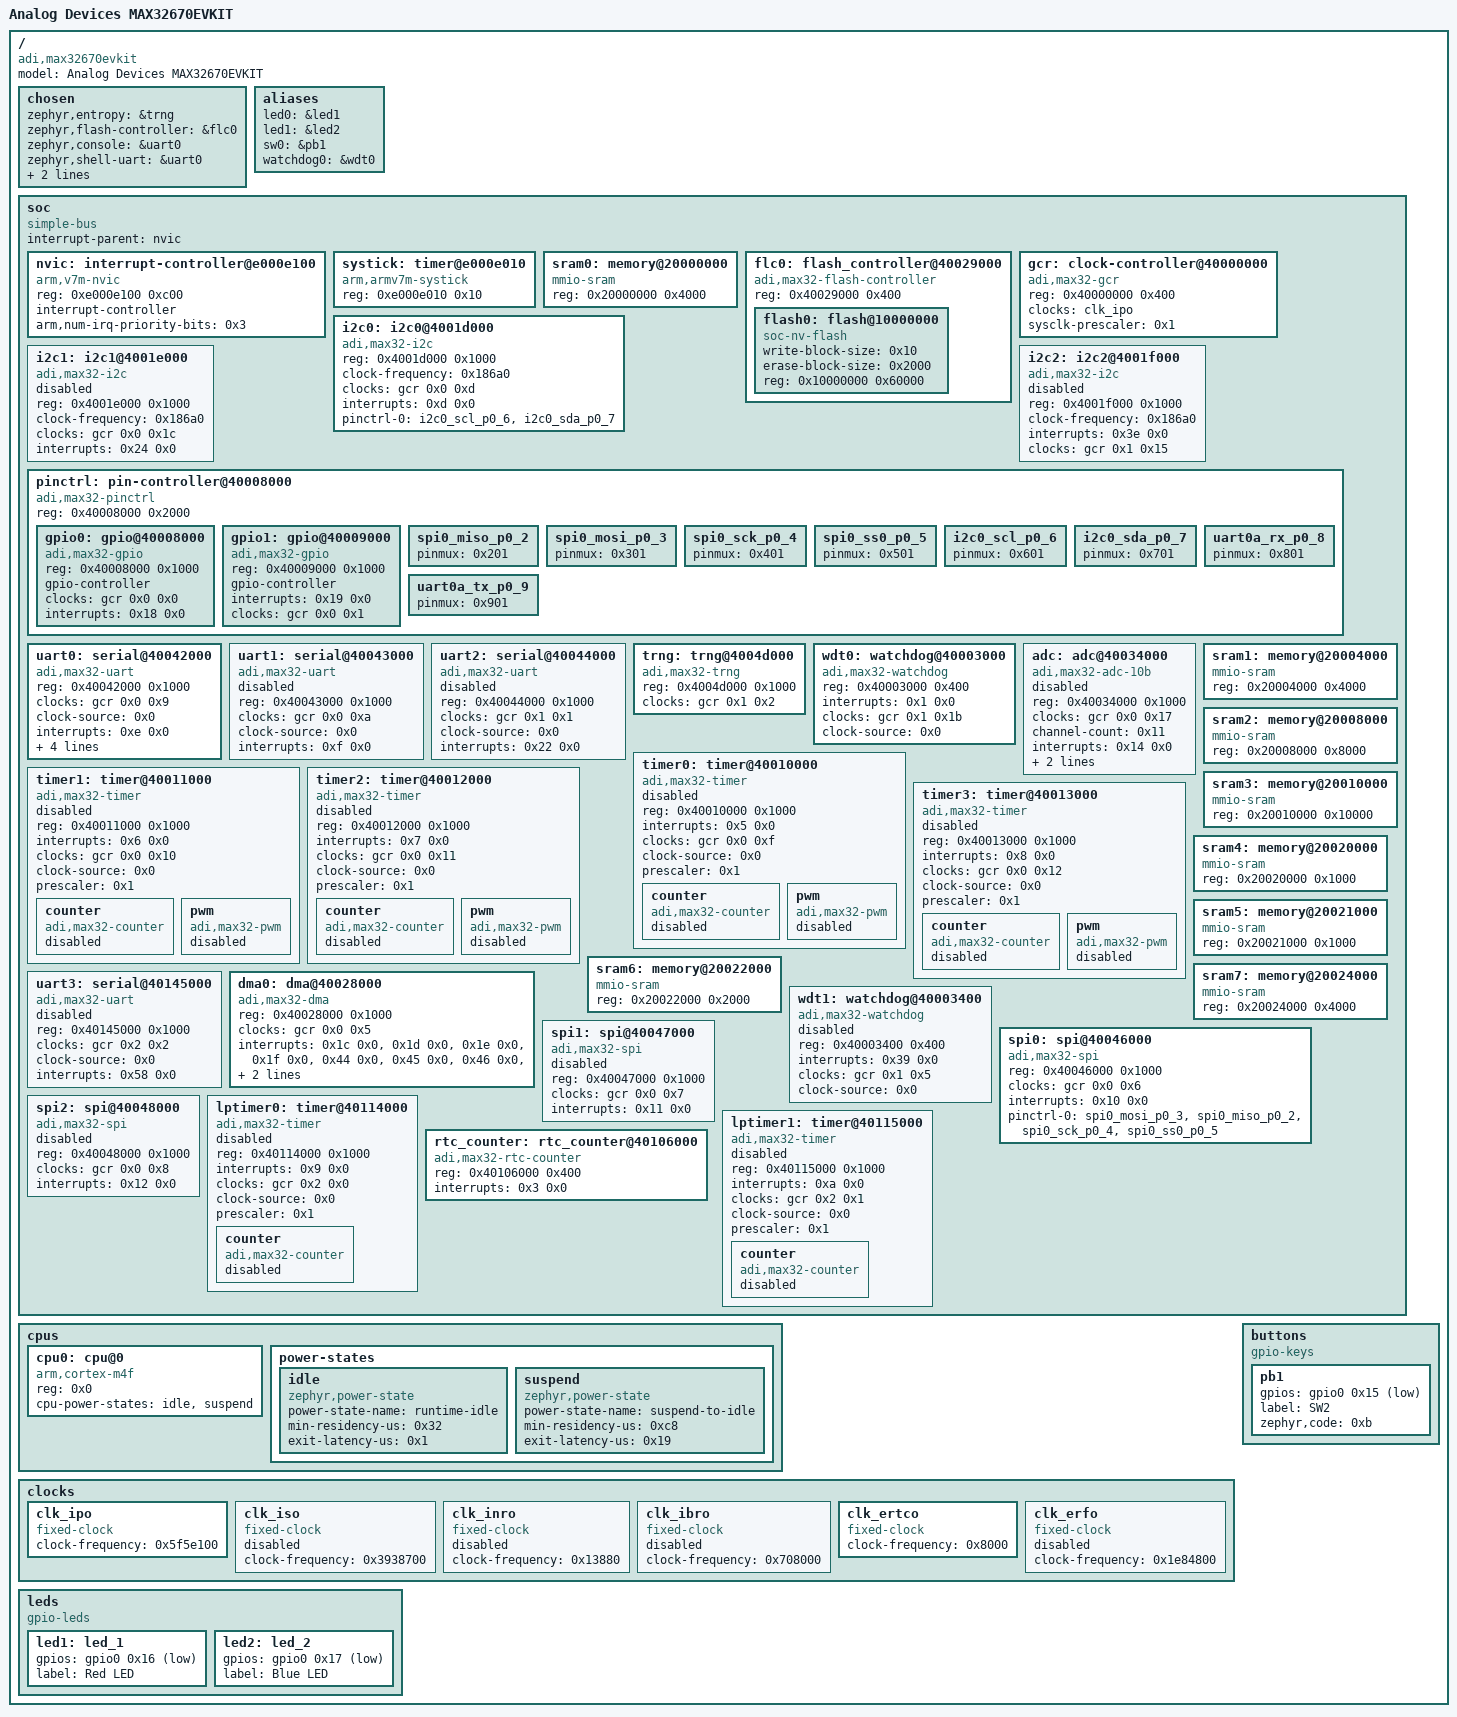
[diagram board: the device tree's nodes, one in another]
/dts-v1/;

/* node '/' defined in zephyr/dts/common/skeleton.dtsi:9 */
/ {
	#address-cells = < 0x1 >;               /* in zephyr/dts/common/skeleton.dtsi:10 */
	#size-cells = < 0x1 >;                  /* in zephyr/dts/common/skeleton.dtsi:11 */
	model = "Analog Devices MAX32670EVKIT"; /* in zephyr/boards/adi/max32670evkit/max32670evkit.dts:15 */
	compatible = "adi,max32670evkit";       /* in zephyr/boards/adi/max32670evkit/max32670evkit.dts:16 */

	/* node '/chosen' defined in zephyr/dts/common/skeleton.dtsi:13 */
	chosen {
		zephyr,entropy = &trng;          /* in zephyr/dts/arm/adi/max32/max32xxx.dtsi:17 */
		zephyr,flash-controller = &flc0; /* in zephyr/dts/arm/adi/max32/max32xxx.dtsi:18 */
		zephyr,console = &uart0;         /* in zephyr/boards/adi/max32670evkit/max32670evkit.dts:19 */
		zephyr,shell-uart = &uart0;      /* in zephyr/boards/adi/max32670evkit/max32670evkit.dts:20 */
		zephyr,sram = &sram3;            /* in zephyr/boards/adi/max32670evkit/max32670evkit.dts:21 */
		zephyr,flash = &flash0;          /* in zephyr/boards/adi/max32670evkit/max32670evkit.dts:22 */
	};

	/* node '/aliases' defined in zephyr/dts/common/skeleton.dtsi:15 */
	aliases {
		led0 = &led1;      /* in zephyr/boards/adi/max32670evkit/max32670evkit.dts:51 */
		led1 = &led2;      /* in zephyr/boards/adi/max32670evkit/max32670evkit.dts:52 */
		sw0 = &pb1;        /* in zephyr/boards/adi/max32670evkit/max32670evkit.dts:53 */
		watchdog0 = &wdt0; /* in zephyr/boards/adi/max32670evkit/max32670evkit.dts:54 */
	};

	/* node '/soc' defined in zephyr/dts/arm/armv7-m.dtsi:6 */
	soc {
		#address-cells = < 0x1 >;     /* in zephyr/dts/arm/armv7-m.dtsi:7 */
		#size-cells = < 0x1 >;        /* in zephyr/dts/arm/armv7-m.dtsi:8 */
		compatible = "simple-bus";    /* in zephyr/dts/arm/armv7-m.dtsi:9 */
		interrupt-parent = < &nvic >; /* in zephyr/dts/arm/armv7-m.dtsi:10 */
		ranges;                       /* in zephyr/dts/arm/armv7-m.dtsi:11 */

		/* node '/soc/interrupt-controller@e000e100' defined in zephyr/dts/arm/armv7-m.dtsi:13 */
		nvic: interrupt-controller@e000e100 {
			#address-cells = < 0x1 >;            /* in zephyr/dts/arm/armv7-m.dtsi:14 */
			compatible = "arm,v7m-nvic";         /* in zephyr/dts/arm/armv7-m.dtsi:15 */
			reg = < 0xe000e100 0xc00 >;          /* in zephyr/dts/arm/armv7-m.dtsi:16 */
			interrupt-controller;                /* in zephyr/dts/arm/armv7-m.dtsi:17 */
			#interrupt-cells = < 0x2 >;          /* in zephyr/dts/arm/armv7-m.dtsi:18 */
			arm,num-irq-priority-bits = < 0x3 >; /* in zephyr/dts/arm/adi/max32/max32xxx.dtsi:337 */
			phandle = < 0x1 >;                   /* in zephyr/dts/arm/armv7-m.dtsi:10 */
		};

		/* node '/soc/timer@e000e010' defined in zephyr/dts/arm/armv7-m.dtsi:21 */
		systick: timer@e000e010 {
			compatible = "arm,armv7m-systick"; /* in zephyr/dts/arm/armv7-m.dtsi:22 */
			reg = < 0xe000e010 0x10 >;         /* in zephyr/dts/arm/armv7-m.dtsi:23 */
		};

		/* node '/soc/memory@20000000' defined in zephyr/dts/arm/adi/max32/max32xxx.dtsi:98 */
		sram0: memory@20000000 {
			compatible = "mmio-sram";    /* in zephyr/dts/arm/adi/max32/max32xxx.dtsi:99 */
			reg = < 0x20000000 0x4000 >; /* in zephyr/dts/arm/adi/max32/max32670.dtsi:12 */
		};

		/* node '/soc/flash_controller@40029000' defined in zephyr/dts/arm/adi/max32/max32xxx.dtsi:103 */
		flc0: flash_controller@40029000 {
			compatible = "adi,max32-flash-controller"; /* in zephyr/dts/arm/adi/max32/max32xxx.dtsi:104 */
			reg = < 0x40029000 0x400 >;                /* in zephyr/dts/arm/adi/max32/max32xxx.dtsi:105 */
			#address-cells = < 0x1 >;                  /* in zephyr/dts/arm/adi/max32/max32xxx.dtsi:107 */
			#size-cells = < 0x1 >;                     /* in zephyr/dts/arm/adi/max32/max32xxx.dtsi:108 */
			status = "okay";                           /* in zephyr/dts/arm/adi/max32/max32xxx.dtsi:109 */

			/* node '/soc/flash_controller@40029000/flash@10000000' defined in zephyr/dts/arm/adi/max32/max32xxx.dtsi:111 */
			flash0: flash@10000000 {
				compatible = "soc-nv-flash";   /* in zephyr/dts/arm/adi/max32/max32xxx.dtsi:112 */
				write-block-size = < 0x10 >;   /* in zephyr/dts/arm/adi/max32/max32xxx.dtsi:114 */
				erase-block-size = < 0x2000 >; /* in zephyr/dts/arm/adi/max32/max32xxx.dtsi:115 */
				reg = < 0x10000000 0x60000 >;  /* in zephyr/dts/arm/adi/max32/max32670.dtsi:16 */
			};
		};

		/* node '/soc/clock-controller@40000000' defined in zephyr/dts/arm/adi/max32/max32xxx.dtsi:119 */
		gcr: clock-controller@40000000 {
			reg = < 0x40000000 0x400 >;   /* in zephyr/dts/arm/adi/max32/max32xxx.dtsi:120 */
			compatible = "adi,max32-gcr"; /* in zephyr/dts/arm/adi/max32/max32xxx.dtsi:121 */
			#clock-cells = < 0x2 >;       /* in zephyr/dts/arm/adi/max32/max32xxx.dtsi:122 */
			clocks = < &clk_ipo >;        /* in zephyr/dts/arm/adi/max32/max32xxx.dtsi:123 */
			sysclk-prescaler = < 0x1 >;   /* in zephyr/dts/arm/adi/max32/max32xxx.dtsi:124 */
			status = "okay";              /* in zephyr/dts/arm/adi/max32/max32xxx.dtsi:125 */
			phandle = < 0x3 >;            /* in zephyr/dts/arm/adi/max32/max32xxx.dtsi:134 */
		};

		/* node '/soc/i2c0@4001d000' defined in zephyr/dts/arm/adi/max32/max32xxx.dtsi:128 */
		i2c0: i2c0@4001d000 {
			compatible = "adi,max32-i2c";                  /* in zephyr/dts/arm/adi/max32/max32xxx.dtsi:129 */
			reg = < 0x4001d000 0x1000 >;                   /* in zephyr/dts/arm/adi/max32/max32xxx.dtsi:130 */
			#address-cells = < 0x1 >;                      /* in zephyr/dts/arm/adi/max32/max32xxx.dtsi:131 */
			#size-cells = < 0x0 >;                         /* in zephyr/dts/arm/adi/max32/max32xxx.dtsi:132 */
			clock-frequency = < 0x186a0 >;                 /* in zephyr/dts/arm/adi/max32/max32xxx.dtsi:133 */
			clocks = < &gcr 0x0 0xd >;                     /* in zephyr/dts/arm/adi/max32/max32xxx.dtsi:134 */
			interrupts = < 0xd 0x0 >;                      /* in zephyr/dts/arm/adi/max32/max32xxx.dtsi:135 */
			status = "okay";                               /* in zephyr/boards/adi/max32670evkit/max32670evkit.dts:91 */
			pinctrl-0 = < &i2c0_scl_p0_6 &i2c0_sda_p0_7 >; /* in zephyr/boards/adi/max32670evkit/max32670evkit.dts:92 */
			pinctrl-names = "default";                     /* in zephyr/boards/adi/max32670evkit/max32670evkit.dts:93 */
		};

		/* node '/soc/i2c1@4001e000' defined in zephyr/dts/arm/adi/max32/max32xxx.dtsi:139 */
		i2c1: i2c1@4001e000 {
			compatible = "adi,max32-i2c";  /* in zephyr/dts/arm/adi/max32/max32xxx.dtsi:140 */
			reg = < 0x4001e000 0x1000 >;   /* in zephyr/dts/arm/adi/max32/max32xxx.dtsi:141 */
			#address-cells = < 0x1 >;      /* in zephyr/dts/arm/adi/max32/max32xxx.dtsi:142 */
			#size-cells = < 0x0 >;         /* in zephyr/dts/arm/adi/max32/max32xxx.dtsi:143 */
			clock-frequency = < 0x186a0 >; /* in zephyr/dts/arm/adi/max32/max32xxx.dtsi:144 */
			clocks = < &gcr 0x0 0x1c >;    /* in zephyr/dts/arm/adi/max32/max32xxx.dtsi:145 */
			interrupts = < 0x24 0x0 >;     /* in zephyr/dts/arm/adi/max32/max32xxx.dtsi:146 */
			status = "disabled";           /* in zephyr/dts/arm/adi/max32/max32xxx.dtsi:147 */
		};

		/* node '/soc/i2c2@4001f000' defined in zephyr/dts/arm/adi/max32/max32xxx.dtsi:150 */
		i2c2: i2c2@4001f000 {
			compatible = "adi,max32-i2c";  /* in zephyr/dts/arm/adi/max32/max32xxx.dtsi:151 */
			reg = < 0x4001f000 0x1000 >;   /* in zephyr/dts/arm/adi/max32/max32xxx.dtsi:152 */
			#address-cells = < 0x1 >;      /* in zephyr/dts/arm/adi/max32/max32xxx.dtsi:153 */
			#size-cells = < 0x0 >;         /* in zephyr/dts/arm/adi/max32/max32xxx.dtsi:154 */
			clock-frequency = < 0x186a0 >; /* in zephyr/dts/arm/adi/max32/max32xxx.dtsi:155 */
			interrupts = < 0x3e 0x0 >;     /* in zephyr/dts/arm/adi/max32/max32xxx.dtsi:157 */
			status = "disabled";           /* in zephyr/dts/arm/adi/max32/max32xxx.dtsi:158 */
			clocks = < &gcr 0x1 0x15 >;    /* in zephyr/dts/arm/adi/max32/max32670.dtsi:24 */
		};

		/* node '/soc/pin-controller@40008000' defined in zephyr/dts/arm/adi/max32/max32xxx.dtsi:161 */
		pinctrl: pin-controller@40008000 {
			compatible = "adi,max32-pinctrl"; /* in zephyr/dts/arm/adi/max32/max32xxx.dtsi:162 */
			#address-cells = < 0x1 >;         /* in zephyr/dts/arm/adi/max32/max32xxx.dtsi:163 */
			#size-cells = < 0x1 >;            /* in zephyr/dts/arm/adi/max32/max32xxx.dtsi:164 */
			reg = < 0x40008000 0x2000 >;      /* in zephyr/dts/arm/adi/max32/max32xxx.dtsi:165 */

			/* node '/soc/pin-controller@40008000/gpio@40008000' defined in zephyr/dts/arm/adi/max32/max32xxx.dtsi:167 */
			gpio0: gpio@40008000 {
				reg = < 0x40008000 0x1000 >;   /* in zephyr/dts/arm/adi/max32/max32xxx.dtsi:168 */
				compatible = "adi,max32-gpio"; /* in zephyr/dts/arm/adi/max32/max32xxx.dtsi:169 */
				gpio-controller;               /* in zephyr/dts/arm/adi/max32/max32xxx.dtsi:170 */
				#gpio-cells = < 0x2 >;         /* in zephyr/dts/arm/adi/max32/max32xxx.dtsi:171 */
				clocks = < &gcr 0x0 0x0 >;     /* in zephyr/dts/arm/adi/max32/max32xxx.dtsi:172 */
				interrupts = < 0x18 0x0 >;     /* in zephyr/dts/arm/adi/max32/max32xxx.dtsi:173 */
				status = "okay";               /* in zephyr/boards/adi/max32670evkit/max32670evkit.dts:79 */
				phandle = < 0xe >;             /* in zephyr/boards/adi/max32670evkit/max32670evkit.dts:29 */
			};

			/* node '/soc/pin-controller@40008000/gpio@40009000' defined in zephyr/dts/arm/adi/max32/max32xxx.dtsi:177 */
			gpio1: gpio@40009000 {
				reg = < 0x40009000 0x1000 >;   /* in zephyr/dts/arm/adi/max32/max32xxx.dtsi:178 */
				compatible = "adi,max32-gpio"; /* in zephyr/dts/arm/adi/max32/max32xxx.dtsi:179 */
				gpio-controller;               /* in zephyr/dts/arm/adi/max32/max32xxx.dtsi:180 */
				#gpio-cells = < 0x2 >;         /* in zephyr/dts/arm/adi/max32/max32xxx.dtsi:181 */
				interrupts = < 0x19 0x0 >;     /* in zephyr/dts/arm/adi/max32/max32xxx.dtsi:182 */
				clocks = < &gcr 0x0 0x1 >;     /* in zephyr/dts/arm/adi/max32/max32xxx.dtsi:183 */
				status = "okay";               /* in zephyr/boards/adi/max32670evkit/max32670evkit.dts:83 */
			};

			/* node '/soc/pin-controller@40008000/spi0_miso_p0_2' defined in zephyr/dts/arm/adi/max32/max32670-pinctrl.dtsi:28 */
			spi0_miso_p0_2: spi0_miso_p0_2 {
				pinmux = < 0x201 >; /* in zephyr/dts/arm/adi/max32/max32670-pinctrl.dtsi:29 */
				phandle = < 0x9 >;  /* in zephyr/boards/adi/max32670evkit/max32670evkit.dts:106 */
			};

			/* node '/soc/pin-controller@40008000/spi0_mosi_p0_3' defined in zephyr/dts/arm/adi/max32/max32670-pinctrl.dtsi:40 */
			spi0_mosi_p0_3: spi0_mosi_p0_3 {
				pinmux = < 0x301 >; /* in zephyr/dts/arm/adi/max32/max32670-pinctrl.dtsi:41 */
				phandle = < 0x8 >;  /* in zephyr/boards/adi/max32670evkit/max32670evkit.dts:106 */
			};

			/* node '/soc/pin-controller@40008000/spi0_sck_p0_4' defined in zephyr/dts/arm/adi/max32/max32670-pinctrl.dtsi:52 */
			spi0_sck_p0_4: spi0_sck_p0_4 {
				pinmux = < 0x401 >; /* in zephyr/dts/arm/adi/max32/max32670-pinctrl.dtsi:53 */
				phandle = < 0xa >;  /* in zephyr/boards/adi/max32670evkit/max32670evkit.dts:106 */
			};

			/* node '/soc/pin-controller@40008000/spi0_ss0_p0_5' defined in zephyr/dts/arm/adi/max32/max32670-pinctrl.dtsi:64 */
			spi0_ss0_p0_5: spi0_ss0_p0_5 {
				pinmux = < 0x501 >; /* in zephyr/dts/arm/adi/max32/max32670-pinctrl.dtsi:65 */
				phandle = < 0xb >;  /* in zephyr/boards/adi/max32670evkit/max32670evkit.dts:106 */
			};

			/* node '/soc/pin-controller@40008000/i2c0_scl_p0_6' defined in zephyr/dts/arm/adi/max32/max32670-pinctrl.dtsi:80 */
			i2c0_scl_p0_6: i2c0_scl_p0_6 {
				pinmux = < 0x601 >; /* in zephyr/dts/arm/adi/max32/max32670-pinctrl.dtsi:81 */
				phandle = < 0x4 >;  /* in zephyr/boards/adi/max32670evkit/max32670evkit.dts:92 */
			};

			/* node '/soc/pin-controller@40008000/i2c0_sda_p0_7' defined in zephyr/dts/arm/adi/max32/max32670-pinctrl.dtsi:92 */
			i2c0_sda_p0_7: i2c0_sda_p0_7 {
				pinmux = < 0x701 >; /* in zephyr/dts/arm/adi/max32/max32670-pinctrl.dtsi:93 */
				phandle = < 0x5 >;  /* in zephyr/boards/adi/max32670evkit/max32670evkit.dts:92 */
			};

			/* node '/soc/pin-controller@40008000/uart0a_rx_p0_8' defined in zephyr/dts/arm/adi/max32/max32670-pinctrl.dtsi:104 */
			uart0a_rx_p0_8: uart0a_rx_p0_8 {
				pinmux = < 0x801 >; /* in zephyr/dts/arm/adi/max32/max32670-pinctrl.dtsi:105 */
				phandle = < 0x7 >;  /* in zephyr/boards/adi/max32670evkit/max32670evkit.dts:59 */
			};

			/* node '/soc/pin-controller@40008000/uart0a_tx_p0_9' defined in zephyr/dts/arm/adi/max32/max32670-pinctrl.dtsi:116 */
			uart0a_tx_p0_9: uart0a_tx_p0_9 {
				pinmux = < 0x901 >; /* in zephyr/dts/arm/adi/max32/max32670-pinctrl.dtsi:117 */
				phandle = < 0x6 >;  /* in zephyr/boards/adi/max32670evkit/max32670evkit.dts:59 */
			};
		};

		/* node '/soc/serial@40042000' defined in zephyr/dts/arm/adi/max32/max32xxx.dtsi:188 */
		uart0: serial@40042000 {
			compatible = "adi,max32-uart";                   /* in zephyr/dts/arm/adi/max32/max32xxx.dtsi:189 */
			reg = < 0x40042000 0x1000 >;                     /* in zephyr/dts/arm/adi/max32/max32xxx.dtsi:190 */
			clocks = < &gcr 0x0 0x9 >;                       /* in zephyr/dts/arm/adi/max32/max32xxx.dtsi:191 */
			clock-source = < 0x0 >;                          /* in zephyr/dts/arm/adi/max32/max32xxx.dtsi:192 */
			interrupts = < 0xe 0x0 >;                        /* in zephyr/dts/arm/adi/max32/max32xxx.dtsi:193 */
			pinctrl-0 = < &uart0a_tx_p0_9 &uart0a_rx_p0_8 >; /* in zephyr/boards/adi/max32670evkit/max32670evkit.dts:59 */
			pinctrl-names = "default";                       /* in zephyr/boards/adi/max32670evkit/max32670evkit.dts:60 */
			current-speed = < 0x1c200 >;                     /* in zephyr/boards/adi/max32670evkit/max32670evkit.dts:61 */
			data-bits = < 0x8 >;                             /* in zephyr/boards/adi/max32670evkit/max32670evkit.dts:62 */
			parity = "none";                                 /* in zephyr/boards/adi/max32670evkit/max32670evkit.dts:63 */
			status = "okay";                                 /* in zephyr/boards/adi/max32670evkit/max32670evkit.dts:64 */
		};

		/* node '/soc/serial@40043000' defined in zephyr/dts/arm/adi/max32/max32xxx.dtsi:197 */
		uart1: serial@40043000 {
			compatible = "adi,max32-uart"; /* in zephyr/dts/arm/adi/max32/max32xxx.dtsi:198 */
			reg = < 0x40043000 0x1000 >;   /* in zephyr/dts/arm/adi/max32/max32xxx.dtsi:199 */
			clocks = < &gcr 0x0 0xa >;     /* in zephyr/dts/arm/adi/max32/max32xxx.dtsi:200 */
			clock-source = < 0x0 >;        /* in zephyr/dts/arm/adi/max32/max32xxx.dtsi:201 */
			interrupts = < 0xf 0x0 >;      /* in zephyr/dts/arm/adi/max32/max32xxx.dtsi:202 */
			status = "disabled";           /* in zephyr/dts/arm/adi/max32/max32xxx.dtsi:203 */
		};

		/* node '/soc/serial@40044000' defined in zephyr/dts/arm/adi/max32/max32xxx.dtsi:206 */
		uart2: serial@40044000 {
			compatible = "adi,max32-uart"; /* in zephyr/dts/arm/adi/max32/max32xxx.dtsi:207 */
			reg = < 0x40044000 0x1000 >;   /* in zephyr/dts/arm/adi/max32/max32xxx.dtsi:208 */
			clocks = < &gcr 0x1 0x1 >;     /* in zephyr/dts/arm/adi/max32/max32xxx.dtsi:209 */
			clock-source = < 0x0 >;        /* in zephyr/dts/arm/adi/max32/max32xxx.dtsi:210 */
			interrupts = < 0x22 0x0 >;     /* in zephyr/dts/arm/adi/max32/max32xxx.dtsi:211 */
			status = "disabled";           /* in zephyr/dts/arm/adi/max32/max32xxx.dtsi:212 */
		};

		/* node '/soc/trng@4004d000' defined in zephyr/dts/arm/adi/max32/max32xxx.dtsi:215 */
		trng: trng@4004d000 {
			compatible = "adi,max32-trng"; /* in zephyr/dts/arm/adi/max32/max32xxx.dtsi:216 */
			reg = < 0x4004d000 0x1000 >;   /* in zephyr/dts/arm/adi/max32/max32xxx.dtsi:217 */
			clocks = < &gcr 0x1 0x2 >;     /* in zephyr/dts/arm/adi/max32/max32xxx.dtsi:218 */
			status = "okay";               /* in zephyr/boards/adi/max32670evkit/max32670evkit.dts:87 */
		};

		/* node '/soc/watchdog@40003000' defined in zephyr/dts/arm/adi/max32/max32xxx.dtsi:222 */
		wdt0: watchdog@40003000 {
			compatible = "adi,max32-watchdog"; /* in zephyr/dts/arm/adi/max32/max32xxx.dtsi:223 */
			reg = < 0x40003000 0x400 >;        /* in zephyr/dts/arm/adi/max32/max32xxx.dtsi:224 */
			interrupts = < 0x1 0x0 >;          /* in zephyr/dts/arm/adi/max32/max32xxx.dtsi:225 */
			clocks = < &gcr 0x1 0x1b >;        /* in zephyr/dts/arm/adi/max32/max32xxx.dtsi:226 */
			clock-source = < 0x0 >;            /* in zephyr/dts/arm/adi/max32/max32xxx.dtsi:227 */
			status = "okay";                   /* in zephyr/boards/adi/max32670evkit/max32670evkit.dts:101 */
		};

		/* node '/soc/adc@40034000' defined in zephyr/dts/arm/adi/max32/max32xxx.dtsi:231 */
		adc: adc@40034000 {
			compatible = "adi,max32-adc-10b",
			             "adi,max32-adc";     /* in zephyr/dts/arm/adi/max32/max32xxx.dtsi:232 */
			reg = < 0x40034000 0x1000 >;      /* in zephyr/dts/arm/adi/max32/max32xxx.dtsi:233 */
			clocks = < &gcr 0x0 0x17 >;       /* in zephyr/dts/arm/adi/max32/max32xxx.dtsi:234 */
			channel-count = < 0x11 >;         /* in zephyr/dts/arm/adi/max32/max32xxx.dtsi:235 */
			#io-channel-cells = < 0x1 >;      /* in zephyr/dts/arm/adi/max32/max32xxx.dtsi:236 */
			interrupts = < 0x14 0x0 >;        /* in zephyr/dts/arm/adi/max32/max32xxx.dtsi:237 */
			resolution = < 0xa >;             /* in zephyr/dts/arm/adi/max32/max32xxx.dtsi:238 */
			vref-mv = < 0x4c4 >;              /* in zephyr/dts/arm/adi/max32/max32xxx.dtsi:239 */
			status = "disabled";              /* in zephyr/dts/arm/adi/max32/max32xxx.dtsi:240 */
		};

		/* node '/soc/timer@40010000' defined in zephyr/dts/arm/adi/max32/max32xxx.dtsi:243 */
		timer0: timer@40010000 {
			compatible = "adi,max32-timer"; /* in zephyr/dts/arm/adi/max32/max32xxx.dtsi:244 */
			reg = < 0x40010000 0x1000 >;    /* in zephyr/dts/arm/adi/max32/max32xxx.dtsi:245 */
			interrupts = < 0x5 0x0 >;       /* in zephyr/dts/arm/adi/max32/max32xxx.dtsi:246 */
			status = "disabled";            /* in zephyr/dts/arm/adi/max32/max32xxx.dtsi:247 */
			clocks = < &gcr 0x0 0xf >;      /* in zephyr/dts/arm/adi/max32/max32xxx.dtsi:248 */
			clock-source = < 0x0 >;         /* in zephyr/dts/arm/adi/max32/max32xxx.dtsi:249 */
			prescaler = < 0x1 >;            /* in zephyr/dts/arm/adi/max32/max32xxx.dtsi:250 */

			/* node '/soc/timer@40010000/counter' defined in zephyr/dts/arm/adi/max32/max32xxx.dtsi:252 */
			counter {
				compatible = "adi,max32-counter"; /* in zephyr/dts/arm/adi/max32/max32xxx.dtsi:253 */
				status = "disabled";              /* in zephyr/dts/arm/adi/max32/max32xxx.dtsi:254 */
			};

			/* node '/soc/timer@40010000/pwm' defined in zephyr/dts/arm/adi/max32/max32xxx.dtsi:257 */
			pwm {
				compatible = "adi,max32-pwm"; /* in zephyr/dts/arm/adi/max32/max32xxx.dtsi:258 */
				status = "disabled";          /* in zephyr/dts/arm/adi/max32/max32xxx.dtsi:259 */
				#pwm-cells = < 0x3 >;         /* in zephyr/dts/arm/adi/max32/max32xxx.dtsi:260 */
			};
		};

		/* node '/soc/timer@40011000' defined in zephyr/dts/arm/adi/max32/max32xxx.dtsi:264 */
		timer1: timer@40011000 {
			compatible = "adi,max32-timer"; /* in zephyr/dts/arm/adi/max32/max32xxx.dtsi:265 */
			reg = < 0x40011000 0x1000 >;    /* in zephyr/dts/arm/adi/max32/max32xxx.dtsi:266 */
			interrupts = < 0x6 0x0 >;       /* in zephyr/dts/arm/adi/max32/max32xxx.dtsi:267 */
			status = "disabled";            /* in zephyr/dts/arm/adi/max32/max32xxx.dtsi:268 */
			clocks = < &gcr 0x0 0x10 >;     /* in zephyr/dts/arm/adi/max32/max32xxx.dtsi:269 */
			clock-source = < 0x0 >;         /* in zephyr/dts/arm/adi/max32/max32xxx.dtsi:270 */
			prescaler = < 0x1 >;            /* in zephyr/dts/arm/adi/max32/max32xxx.dtsi:271 */

			/* node '/soc/timer@40011000/counter' defined in zephyr/dts/arm/adi/max32/max32xxx.dtsi:273 */
			counter {
				compatible = "adi,max32-counter"; /* in zephyr/dts/arm/adi/max32/max32xxx.dtsi:274 */
				status = "disabled";              /* in zephyr/dts/arm/adi/max32/max32xxx.dtsi:275 */
			};

			/* node '/soc/timer@40011000/pwm' defined in zephyr/dts/arm/adi/max32/max32xxx.dtsi:278 */
			pwm {
				compatible = "adi,max32-pwm"; /* in zephyr/dts/arm/adi/max32/max32xxx.dtsi:279 */
				status = "disabled";          /* in zephyr/dts/arm/adi/max32/max32xxx.dtsi:280 */
				#pwm-cells = < 0x3 >;         /* in zephyr/dts/arm/adi/max32/max32xxx.dtsi:281 */
			};
		};

		/* node '/soc/timer@40012000' defined in zephyr/dts/arm/adi/max32/max32xxx.dtsi:285 */
		timer2: timer@40012000 {
			compatible = "adi,max32-timer"; /* in zephyr/dts/arm/adi/max32/max32xxx.dtsi:286 */
			reg = < 0x40012000 0x1000 >;    /* in zephyr/dts/arm/adi/max32/max32xxx.dtsi:287 */
			interrupts = < 0x7 0x0 >;       /* in zephyr/dts/arm/adi/max32/max32xxx.dtsi:288 */
			status = "disabled";            /* in zephyr/dts/arm/adi/max32/max32xxx.dtsi:289 */
			clocks = < &gcr 0x0 0x11 >;     /* in zephyr/dts/arm/adi/max32/max32xxx.dtsi:290 */
			clock-source = < 0x0 >;         /* in zephyr/dts/arm/adi/max32/max32xxx.dtsi:291 */
			prescaler = < 0x1 >;            /* in zephyr/dts/arm/adi/max32/max32xxx.dtsi:292 */

			/* node '/soc/timer@40012000/counter' defined in zephyr/dts/arm/adi/max32/max32xxx.dtsi:294 */
			counter {
				compatible = "adi,max32-counter"; /* in zephyr/dts/arm/adi/max32/max32xxx.dtsi:295 */
				status = "disabled";              /* in zephyr/dts/arm/adi/max32/max32xxx.dtsi:296 */
			};

			/* node '/soc/timer@40012000/pwm' defined in zephyr/dts/arm/adi/max32/max32xxx.dtsi:299 */
			pwm {
				compatible = "adi,max32-pwm"; /* in zephyr/dts/arm/adi/max32/max32xxx.dtsi:300 */
				status = "disabled";          /* in zephyr/dts/arm/adi/max32/max32xxx.dtsi:301 */
				#pwm-cells = < 0x3 >;         /* in zephyr/dts/arm/adi/max32/max32xxx.dtsi:302 */
			};
		};

		/* node '/soc/timer@40013000' defined in zephyr/dts/arm/adi/max32/max32xxx.dtsi:306 */
		timer3: timer@40013000 {
			compatible = "adi,max32-timer"; /* in zephyr/dts/arm/adi/max32/max32xxx.dtsi:307 */
			reg = < 0x40013000 0x1000 >;    /* in zephyr/dts/arm/adi/max32/max32xxx.dtsi:308 */
			interrupts = < 0x8 0x0 >;       /* in zephyr/dts/arm/adi/max32/max32xxx.dtsi:309 */
			status = "disabled";            /* in zephyr/dts/arm/adi/max32/max32xxx.dtsi:310 */
			clocks = < &gcr 0x0 0x12 >;     /* in zephyr/dts/arm/adi/max32/max32xxx.dtsi:311 */
			clock-source = < 0x0 >;         /* in zephyr/dts/arm/adi/max32/max32xxx.dtsi:312 */
			prescaler = < 0x1 >;            /* in zephyr/dts/arm/adi/max32/max32xxx.dtsi:313 */

			/* node '/soc/timer@40013000/counter' defined in zephyr/dts/arm/adi/max32/max32xxx.dtsi:315 */
			counter {
				compatible = "adi,max32-counter"; /* in zephyr/dts/arm/adi/max32/max32xxx.dtsi:316 */
				status = "disabled";              /* in zephyr/dts/arm/adi/max32/max32xxx.dtsi:317 */
			};

			/* node '/soc/timer@40013000/pwm' defined in zephyr/dts/arm/adi/max32/max32xxx.dtsi:320 */
			pwm {
				compatible = "adi,max32-pwm"; /* in zephyr/dts/arm/adi/max32/max32xxx.dtsi:321 */
				status = "disabled";          /* in zephyr/dts/arm/adi/max32/max32xxx.dtsi:322 */
				#pwm-cells = < 0x3 >;         /* in zephyr/dts/arm/adi/max32/max32xxx.dtsi:323 */
			};
		};

		/* node '/soc/memory@20004000' defined in zephyr/dts/arm/adi/max32/max32670.dtsi:32 */
		sram1: memory@20004000 {
			compatible = "mmio-sram";    /* in zephyr/dts/arm/adi/max32/max32670.dtsi:33 */
			reg = < 0x20004000 0x4000 >; /* in zephyr/dts/arm/adi/max32/max32670.dtsi:34 */
		};

		/* node '/soc/memory@20008000' defined in zephyr/dts/arm/adi/max32/max32670.dtsi:37 */
		sram2: memory@20008000 {
			compatible = "mmio-sram";    /* in zephyr/dts/arm/adi/max32/max32670.dtsi:38 */
			reg = < 0x20008000 0x8000 >; /* in zephyr/dts/arm/adi/max32/max32670.dtsi:39 */
		};

		/* node '/soc/memory@20010000' defined in zephyr/dts/arm/adi/max32/max32670.dtsi:42 */
		sram3: memory@20010000 {
			compatible = "mmio-sram";     /* in zephyr/dts/arm/adi/max32/max32670.dtsi:43 */
			reg = < 0x20010000 0x10000 >; /* in zephyr/dts/arm/adi/max32/max32670.dtsi:44 */
		};

		/* node '/soc/memory@20020000' defined in zephyr/dts/arm/adi/max32/max32670.dtsi:47 */
		sram4: memory@20020000 {
			compatible = "mmio-sram";    /* in zephyr/dts/arm/adi/max32/max32670.dtsi:48 */
			reg = < 0x20020000 0x1000 >; /* in zephyr/dts/arm/adi/max32/max32670.dtsi:49 */
		};

		/* node '/soc/memory@20021000' defined in zephyr/dts/arm/adi/max32/max32670.dtsi:52 */
		sram5: memory@20021000 {
			compatible = "mmio-sram";    /* in zephyr/dts/arm/adi/max32/max32670.dtsi:53 */
			reg = < 0x20021000 0x1000 >; /* in zephyr/dts/arm/adi/max32/max32670.dtsi:54 */
		};

		/* node '/soc/memory@20022000' defined in zephyr/dts/arm/adi/max32/max32670.dtsi:57 */
		sram6: memory@20022000 {
			compatible = "mmio-sram";    /* in zephyr/dts/arm/adi/max32/max32670.dtsi:58 */
			reg = < 0x20022000 0x2000 >; /* in zephyr/dts/arm/adi/max32/max32670.dtsi:59 */
		};

		/* node '/soc/memory@20024000' defined in zephyr/dts/arm/adi/max32/max32670.dtsi:62 */
		sram7: memory@20024000 {
			compatible = "mmio-sram";    /* in zephyr/dts/arm/adi/max32/max32670.dtsi:63 */
			reg = < 0x20024000 0x4000 >; /* in zephyr/dts/arm/adi/max32/max32670.dtsi:64 */
		};

		/* node '/soc/serial@40145000' defined in zephyr/dts/arm/adi/max32/max32670.dtsi:67 */
		uart3: serial@40145000 {
			compatible = "adi,max32-uart"; /* in zephyr/dts/arm/adi/max32/max32670.dtsi:68 */
			reg = < 0x40145000 0x1000 >;   /* in zephyr/dts/arm/adi/max32/max32670.dtsi:69 */
			clocks = < &gcr 0x2 0x2 >;     /* in zephyr/dts/arm/adi/max32/max32670.dtsi:70 */
			clock-source = < 0x0 >;        /* in zephyr/dts/arm/adi/max32/max32670.dtsi:71 */
			interrupts = < 0x58 0x0 >;     /* in zephyr/dts/arm/adi/max32/max32670.dtsi:72 */
			status = "disabled";           /* in zephyr/dts/arm/adi/max32/max32670.dtsi:73 */
		};

		/* node '/soc/dma@40028000' defined in zephyr/dts/arm/adi/max32/max32670.dtsi:76 */
		dma0: dma@40028000 {
			compatible = "adi,max32-dma"; /* in zephyr/dts/arm/adi/max32/max32670.dtsi:77 */
			reg = < 0x40028000 0x1000 >;  /* in zephyr/dts/arm/adi/max32/max32670.dtsi:78 */
			clocks = < &gcr 0x0 0x5 >;    /* in zephyr/dts/arm/adi/max32/max32670.dtsi:79 */
			interrupts = < 0x1c 0x0 >,
			             < 0x1d 0x0 >,
			             < 0x1e 0x0 >,
			             < 0x1f 0x0 >,
			             < 0x44 0x0 >,
			             < 0x45 0x0 >,
			             < 0x46 0x0 >,
			             < 0x47 0x0 >;    /* in zephyr/dts/arm/adi/max32/max32670.dtsi:80 */
			dma-channels = < 0x8 >;       /* in zephyr/dts/arm/adi/max32/max32670.dtsi:81 */
			#dma-cells = < 0x2 >;         /* in zephyr/dts/arm/adi/max32/max32670.dtsi:83 */
			status = "okay";              /* in zephyr/boards/adi/max32670evkit/max32670evkit.dts:97 */
		};

		/* node '/soc/watchdog@40003400' defined in zephyr/dts/arm/adi/max32/max32670.dtsi:86 */
		wdt1: watchdog@40003400 {
			compatible = "adi,max32-watchdog"; /* in zephyr/dts/arm/adi/max32/max32670.dtsi:87 */
			reg = < 0x40003400 0x400 >;        /* in zephyr/dts/arm/adi/max32/max32670.dtsi:88 */
			interrupts = < 0x39 0x0 >;         /* in zephyr/dts/arm/adi/max32/max32670.dtsi:89 */
			clocks = < &gcr 0x1 0x5 >;         /* in zephyr/dts/arm/adi/max32/max32670.dtsi:90 */
			clock-source = < 0x0 >;            /* in zephyr/dts/arm/adi/max32/max32670.dtsi:91 */
			status = "disabled";               /* in zephyr/dts/arm/adi/max32/max32670.dtsi:92 */
		};

		/* node '/soc/spi@40046000' defined in zephyr/dts/arm/adi/max32/max32670.dtsi:95 */
		spi0: spi@40046000 {
			compatible = "adi,max32-spi";                                                  /* in zephyr/dts/arm/adi/max32/max32670.dtsi:96 */
			reg = < 0x40046000 0x1000 >;                                                   /* in zephyr/dts/arm/adi/max32/max32670.dtsi:97 */
			#address-cells = < 0x1 >;                                                      /* in zephyr/dts/arm/adi/max32/max32670.dtsi:98 */
			#size-cells = < 0x0 >;                                                         /* in zephyr/dts/arm/adi/max32/max32670.dtsi:99 */
			clocks = < &gcr 0x0 0x6 >;                                                     /* in zephyr/dts/arm/adi/max32/max32670.dtsi:100 */
			interrupts = < 0x10 0x0 >;                                                     /* in zephyr/dts/arm/adi/max32/max32670.dtsi:101 */
			status = "okay";                                                               /* in zephyr/boards/adi/max32670evkit/max32670evkit.dts:105 */
			pinctrl-0 = < &spi0_mosi_p0_3 &spi0_miso_p0_2 &spi0_sck_p0_4 &spi0_ss0_p0_5 >; /* in zephyr/boards/adi/max32670evkit/max32670evkit.dts:106 */
			pinctrl-names = "default";                                                     /* in zephyr/boards/adi/max32670evkit/max32670evkit.dts:107 */
		};

		/* node '/soc/spi@40047000' defined in zephyr/dts/arm/adi/max32/max32670.dtsi:105 */
		spi1: spi@40047000 {
			compatible = "adi,max32-spi"; /* in zephyr/dts/arm/adi/max32/max32670.dtsi:106 */
			reg = < 0x40047000 0x1000 >;  /* in zephyr/dts/arm/adi/max32/max32670.dtsi:107 */
			#address-cells = < 0x1 >;     /* in zephyr/dts/arm/adi/max32/max32670.dtsi:108 */
			#size-cells = < 0x0 >;        /* in zephyr/dts/arm/adi/max32/max32670.dtsi:109 */
			clocks = < &gcr 0x0 0x7 >;    /* in zephyr/dts/arm/adi/max32/max32670.dtsi:110 */
			interrupts = < 0x11 0x0 >;    /* in zephyr/dts/arm/adi/max32/max32670.dtsi:111 */
			status = "disabled";          /* in zephyr/dts/arm/adi/max32/max32670.dtsi:112 */
		};

		/* node '/soc/spi@40048000' defined in zephyr/dts/arm/adi/max32/max32670.dtsi:115 */
		spi2: spi@40048000 {
			compatible = "adi,max32-spi"; /* in zephyr/dts/arm/adi/max32/max32670.dtsi:116 */
			reg = < 0x40048000 0x1000 >;  /* in zephyr/dts/arm/adi/max32/max32670.dtsi:117 */
			#address-cells = < 0x1 >;     /* in zephyr/dts/arm/adi/max32/max32670.dtsi:118 */
			#size-cells = < 0x0 >;        /* in zephyr/dts/arm/adi/max32/max32670.dtsi:119 */
			clocks = < &gcr 0x0 0x8 >;    /* in zephyr/dts/arm/adi/max32/max32670.dtsi:120 */
			interrupts = < 0x12 0x0 >;    /* in zephyr/dts/arm/adi/max32/max32670.dtsi:121 */
			status = "disabled";          /* in zephyr/dts/arm/adi/max32/max32670.dtsi:122 */
		};

		/* node '/soc/timer@40114000' defined in zephyr/dts/arm/adi/max32/max32670.dtsi:125 */
		lptimer0: timer@40114000 {
			compatible = "adi,max32-timer"; /* in zephyr/dts/arm/adi/max32/max32670.dtsi:126 */
			reg = < 0x40114000 0x1000 >;    /* in zephyr/dts/arm/adi/max32/max32670.dtsi:127 */
			interrupts = < 0x9 0x0 >;       /* in zephyr/dts/arm/adi/max32/max32670.dtsi:128 */
			status = "disabled";            /* in zephyr/dts/arm/adi/max32/max32670.dtsi:129 */
			clocks = < &gcr 0x2 0x0 >;      /* in zephyr/dts/arm/adi/max32/max32670.dtsi:130 */
			clock-source = < 0x0 >;         /* in zephyr/dts/arm/adi/max32/max32670.dtsi:131 */
			prescaler = < 0x1 >;            /* in zephyr/dts/arm/adi/max32/max32670.dtsi:132 */

			/* node '/soc/timer@40114000/counter' defined in zephyr/dts/arm/adi/max32/max32670.dtsi:134 */
			counter {
				compatible = "adi,max32-counter"; /* in zephyr/dts/arm/adi/max32/max32670.dtsi:135 */
				status = "disabled";              /* in zephyr/dts/arm/adi/max32/max32670.dtsi:136 */
			};
		};

		/* node '/soc/timer@40115000' defined in zephyr/dts/arm/adi/max32/max32670.dtsi:140 */
		lptimer1: timer@40115000 {
			compatible = "adi,max32-timer"; /* in zephyr/dts/arm/adi/max32/max32670.dtsi:141 */
			reg = < 0x40115000 0x1000 >;    /* in zephyr/dts/arm/adi/max32/max32670.dtsi:142 */
			interrupts = < 0xa 0x0 >;       /* in zephyr/dts/arm/adi/max32/max32670.dtsi:143 */
			status = "disabled";            /* in zephyr/dts/arm/adi/max32/max32670.dtsi:144 */
			clocks = < &gcr 0x2 0x1 >;      /* in zephyr/dts/arm/adi/max32/max32670.dtsi:145 */
			clock-source = < 0x0 >;         /* in zephyr/dts/arm/adi/max32/max32670.dtsi:146 */
			prescaler = < 0x1 >;            /* in zephyr/dts/arm/adi/max32/max32670.dtsi:147 */

			/* node '/soc/timer@40115000/counter' defined in zephyr/dts/arm/adi/max32/max32670.dtsi:149 */
			counter {
				compatible = "adi,max32-counter"; /* in zephyr/dts/arm/adi/max32/max32670.dtsi:150 */
				status = "disabled";              /* in zephyr/dts/arm/adi/max32/max32670.dtsi:151 */
			};
		};

		/* node '/soc/rtc_counter@40106000' defined in zephyr/dts/arm/adi/max32/max32670.dtsi:155 */
		rtc_counter: rtc_counter@40106000 {
			compatible = "adi,max32-rtc-counter"; /* in zephyr/dts/arm/adi/max32/max32670.dtsi:156 */
			reg = < 0x40106000 0x400 >;           /* in zephyr/dts/arm/adi/max32/max32670.dtsi:157 */
			interrupts = < 0x3 0x0 >;             /* in zephyr/dts/arm/adi/max32/max32670.dtsi:158 */
			status = "okay";                      /* in zephyr/boards/adi/max32670evkit/max32670evkit.dts:111 */
		};
	};

	/* node '/cpus' defined in zephyr/dts/arm/adi/max32/max32xxx.dtsi:21 */
	cpus {
		#address-cells = < 0x1 >; /* in zephyr/dts/arm/adi/max32/max32xxx.dtsi:22 */
		#size-cells = < 0x0 >;    /* in zephyr/dts/arm/adi/max32/max32xxx.dtsi:23 */

		/* node '/cpus/cpu@0' defined in zephyr/dts/arm/adi/max32/max32xxx.dtsi:25 */
		cpu0: cpu@0 {
			device_type = "cpu";                   /* in zephyr/dts/arm/adi/max32/max32xxx.dtsi:26 */
			compatible = "arm,cortex-m4f";         /* in zephyr/dts/arm/adi/max32/max32xxx.dtsi:27 */
			reg = < 0x0 >;                         /* in zephyr/dts/arm/adi/max32/max32xxx.dtsi:28 */
			cpu-power-states = < &idle &suspend >; /* in zephyr/dts/arm/adi/max32/max32xxx.dtsi:29 */
		};

		/* node '/cpus/power-states' defined in zephyr/dts/arm/adi/max32/max32xxx.dtsi:32 */
		power-states {

			/* node '/cpus/power-states/idle' defined in zephyr/dts/arm/adi/max32/max32xxx.dtsi:34 */
			idle: idle {
				compatible = "zephyr,power-state"; /* in zephyr/dts/arm/adi/max32/max32xxx.dtsi:35 */
				power-state-name = "runtime-idle"; /* in zephyr/dts/arm/adi/max32/max32xxx.dtsi:36 */
				min-residency-us = < 0x32 >;       /* in zephyr/dts/arm/adi/max32/max32xxx.dtsi:37 */
				exit-latency-us = < 0x1 >;         /* in zephyr/dts/arm/adi/max32/max32xxx.dtsi:39 */
				phandle = < 0xc >;                 /* in zephyr/dts/arm/adi/max32/max32xxx.dtsi:29 */
			};

			/* node '/cpus/power-states/suspend' defined in zephyr/dts/arm/adi/max32/max32xxx.dtsi:43 */
			suspend: suspend {
				compatible = "zephyr,power-state";    /* in zephyr/dts/arm/adi/max32/max32xxx.dtsi:44 */
				power-state-name = "suspend-to-idle"; /* in zephyr/dts/arm/adi/max32/max32xxx.dtsi:45 */
				min-residency-us = < 0xc8 >;          /* in zephyr/dts/arm/adi/max32/max32xxx.dtsi:46 */
				exit-latency-us = < 0x19 >;           /* in zephyr/dts/arm/adi/max32/max32xxx.dtsi:48 */
				phandle = < 0xd >;                    /* in zephyr/dts/arm/adi/max32/max32xxx.dtsi:29 */
			};
		};
	};

	/* node '/clocks' defined in zephyr/dts/arm/adi/max32/max32xxx.dtsi:53 */
	clocks {

		/* node '/clocks/clk_ipo' defined in zephyr/dts/arm/adi/max32/max32xxx.dtsi:54 */
		clk_ipo: clk_ipo {
			compatible = "fixed-clock";      /* in zephyr/dts/arm/adi/max32/max32xxx.dtsi:55 */
			#clock-cells = < 0x0 >;          /* in zephyr/dts/arm/adi/max32/max32xxx.dtsi:56 */
			clock-frequency = < 0x5f5e100 >; /* in zephyr/dts/arm/adi/max32/max32xxx.dtsi:57 */
			status = "okay";                 /* in zephyr/boards/adi/max32670evkit/max32670evkit.dts:68 */
			phandle = < 0x2 >;               /* in zephyr/dts/arm/adi/max32/max32xxx.dtsi:123 */
		};

		/* node '/clocks/clk_iso' defined in zephyr/dts/arm/adi/max32/max32xxx.dtsi:61 */
		clk_iso: clk_iso {
			compatible = "fixed-clock";      /* in zephyr/dts/arm/adi/max32/max32xxx.dtsi:62 */
			#clock-cells = < 0x0 >;          /* in zephyr/dts/arm/adi/max32/max32xxx.dtsi:63 */
			clock-frequency = < 0x3938700 >; /* in zephyr/dts/arm/adi/max32/max32xxx.dtsi:64 */
			status = "disabled";             /* in zephyr/dts/arm/adi/max32/max32xxx.dtsi:65 */
		};

		/* node '/clocks/clk_inro' defined in zephyr/dts/arm/adi/max32/max32xxx.dtsi:68 */
		clk_inro: clk_inro {
			compatible = "fixed-clock";    /* in zephyr/dts/arm/adi/max32/max32xxx.dtsi:69 */
			#clock-cells = < 0x0 >;        /* in zephyr/dts/arm/adi/max32/max32xxx.dtsi:70 */
			status = "disabled";           /* in zephyr/dts/arm/adi/max32/max32xxx.dtsi:72 */
			clock-frequency = < 0x13880 >; /* in zephyr/dts/arm/adi/max32/max32670.dtsi:20 */
		};

		/* node '/clocks/clk_ibro' defined in zephyr/dts/arm/adi/max32/max32xxx.dtsi:75 */
		clk_ibro: clk_ibro {
			compatible = "fixed-clock";     /* in zephyr/dts/arm/adi/max32/max32xxx.dtsi:76 */
			#clock-cells = < 0x0 >;         /* in zephyr/dts/arm/adi/max32/max32xxx.dtsi:77 */
			clock-frequency = < 0x708000 >; /* in zephyr/dts/arm/adi/max32/max32xxx.dtsi:78 */
			status = "disabled";            /* in zephyr/dts/arm/adi/max32/max32xxx.dtsi:79 */
		};

		/* node '/clocks/clk_ertco' defined in zephyr/dts/arm/adi/max32/max32xxx.dtsi:82 */
		clk_ertco: clk_ertco {
			compatible = "fixed-clock";   /* in zephyr/dts/arm/adi/max32/max32xxx.dtsi:83 */
			#clock-cells = < 0x0 >;       /* in zephyr/dts/arm/adi/max32/max32xxx.dtsi:84 */
			clock-frequency = < 0x8000 >; /* in zephyr/dts/arm/adi/max32/max32xxx.dtsi:85 */
			status = "okay";              /* in zephyr/boards/adi/max32670evkit/max32670evkit.dts:75 */
		};

		/* node '/clocks/clk_erfo' defined in zephyr/dts/arm/adi/max32/max32xxx.dtsi:89 */
		clk_erfo: clk_erfo {
			compatible = "fixed-clock";      /* in zephyr/dts/arm/adi/max32/max32xxx.dtsi:90 */
			#clock-cells = < 0x0 >;          /* in zephyr/dts/arm/adi/max32/max32xxx.dtsi:91 */
			clock-frequency = < 0x1e84800 >; /* in zephyr/dts/arm/adi/max32/max32xxx.dtsi:92 */
			status = "disabled";             /* in zephyr/dts/arm/adi/max32/max32xxx.dtsi:93 */
		};
	};

	/* node '/leds' defined in zephyr/boards/adi/max32670evkit/max32670evkit.dts:25 */
	leds {
		compatible = "gpio-leds"; /* in zephyr/boards/adi/max32670evkit/max32670evkit.dts:26 */

		/* node '/leds/led_1' defined in zephyr/boards/adi/max32670evkit/max32670evkit.dts:28 */
		led1: led_1 {
			gpios = < &gpio0 0x16 0x1 >; /* in zephyr/boards/adi/max32670evkit/max32670evkit.dts:29 */
			label = "Red LED";           /* in zephyr/boards/adi/max32670evkit/max32670evkit.dts:30 */
		};

		/* node '/leds/led_2' defined in zephyr/boards/adi/max32670evkit/max32670evkit.dts:33 */
		led2: led_2 {
			gpios = < &gpio0 0x17 0x1 >; /* in zephyr/boards/adi/max32670evkit/max32670evkit.dts:34 */
			label = "Blue LED";          /* in zephyr/boards/adi/max32670evkit/max32670evkit.dts:35 */
		};
	};

	/* node '/buttons' defined in zephyr/boards/adi/max32670evkit/max32670evkit.dts:39 */
	buttons {
		compatible = "gpio-keys"; /* in zephyr/boards/adi/max32670evkit/max32670evkit.dts:40 */

		/* node '/buttons/pb1' defined in zephyr/boards/adi/max32670evkit/max32670evkit.dts:42 */
		pb1: pb1 {
			gpios = < &gpio0 0x15 0x11 >; /* in zephyr/boards/adi/max32670evkit/max32670evkit.dts:43 */
			label = "SW2";                /* in zephyr/boards/adi/max32670evkit/max32670evkit.dts:44 */
			zephyr,code = < 0xb >;        /* in zephyr/boards/adi/max32670evkit/max32670evkit.dts:45 */
		};
	};
};
